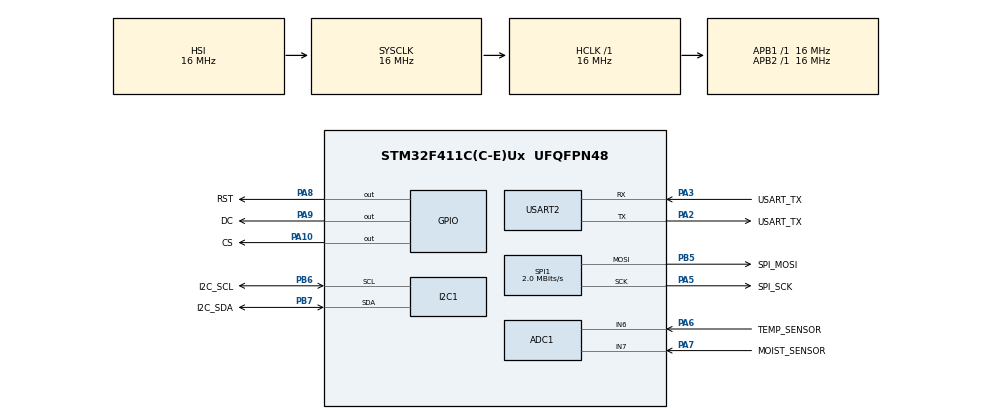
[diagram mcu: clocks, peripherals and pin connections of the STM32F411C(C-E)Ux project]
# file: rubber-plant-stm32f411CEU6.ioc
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ADC1.Channel-2\#ChannelRegularConversion=ADC_CHANNEL_6
ADC1.Channel-3\#ChannelRegularConversion=ADC_CHANNEL_7
ADC1.ClockPrescaler=ADC_CLOCK_SYNC_PCLK_DIV8
ADC1.EOCSelection=ADC_EOC_SEQ_CONV
ADC1.NbrOfConversion=2
ADC1.NbrOfConversionFlag=1
ADC1.Rank-2\#ChannelRegularConversion=1
ADC1.Rank-3\#ChannelRegularConversion=2
ADC1.SamplingTime-2\#ChannelRegularConversion=ADC_SAMPLETIME_480CYCLES
ADC1.SamplingTime-3\#ChannelRegularConversion=ADC_SAMPLETIME_480CYCLES
ADC1.ScanConvMode=ENABLE
ADC1.master=1
Dma.ADC1.0.Direction=DMA_PERIPH_TO_MEMORY
Dma.ADC1.0.FIFOMode=DMA_FIFOMODE_DISABLE
Dma.ADC1.0.Instance=DMA2_Stream0
Dma.ADC1.0.MemDataAlignment=DMA_MDATAALIGN_HALFWORD
Dma.ADC1.0.MemInc=DMA_MINC_ENABLE
Dma.ADC1.0.Mode=DMA_NORMAL
Dma.ADC1.0.PeriphDataAlignment=DMA_PDATAALIGN_HALFWORD
Dma.ADC1.0.PeriphInc=DMA_PINC_DISABLE
Dma.ADC1.0.Priority=DMA_PRIORITY_LOW
Dma.Request0=ADC1
Mcu.Family=STM32F4
Mcu.Name=STM32F411C(C-E)Ux
Mcu.Package=UFQFPN48
NVIC.DMA2_Stream0_IRQn=true\:0\:0\:false\:false\:true\:false\:true\:true
NVIC.PriorityGroup=NVIC_PRIORITYGROUP_4
PA10.GPIO_Label=CS
PA10.Signal=GPIO_Output
PA2.GPIO_Label=USART_TX
PA2.Mode=Asynchronous
PA2.Signal=USART2_TX
PA3.GPIO_Label=USART_TX
PA3.Mode=Asynchronous
PA3.Signal=USART2_RX
PA5.GPIO_Label=SPI_SCK
PA5.Mode=TX_Only_Simplex_Unidirect_Master
PA5.Signal=SPI1_SCK
PA6.GPIO_Label=TEMP_SENSOR
PA6.Signal=ADCx_IN6
PA7.GPIO_Label=MOIST_SENSOR
PA7.Signal=ADCx_IN7
PA8.GPIO_Label=RST
PA8.Signal=GPIO_Output
PA9.GPIO_Label=DC
PA9.Signal=GPIO_Output
PB5.GPIO_Label=SPI_MOSI
PB5.Mode=TX_Only_Simplex_Unidirect_Master
PB5.Signal=SPI1_MOSI
PB6.GPIO_Label=I2C_SCL
PB6.Mode=I2C
PB6.Signal=I2C1_SCL
PB7.GPIO_Label=I2C_SDA
PB7.Mode=I2C
PB7.Signal=I2C1_SDA
ProjectManager.HeapSize=0x200
ProjectManager.StackSize=0x400
ProjectManager.TargetToolchain=CMake
RCC.AHBFreq_Value=16000000
RCC.APB1Freq_Value=16000000
RCC.APB2Freq_Value=16000000
RCC.CortexFreq_Value=16000000
RCC.HSE_VALUE=25000000
RCC.HSI_VALUE=16000000
RCC.LSE_VALUE=32768
RCC.SYSCLKFreq_VALUE=16000000
RCC.VCOOutputFreq_Value=192000000
SH.ADCx_IN6.0=ADC1_IN6,IN6
SH.ADCx_IN7.0=ADC1_IN7,IN7
SPI1.BaudRatePrescaler=SPI_BAUDRATEPRESCALER_8
SPI1.CalculateBaudRate=2.0 MBits/s
SPI1.Direction=SPI_DIRECTION_2LINES
SPI1.Mode=SPI_MODE_MASTER
SPI1.VirtualType=VM_MASTER
USART2.VirtualMode=VM_ASYNC
board=custom

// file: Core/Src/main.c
/* USER CODE BEGIN Header */
/**
  ******************************************************************************
  * @file           : main.c
  * @brief          : Main program body
  ******************************************************************************
  * @attention
  *
  * Copyright (c) 2026 STMicroelectronics.
  * All rights reserved.
  *
  * This software is licensed under terms that can be found in the LICENSE file
  * in the root directory of this software component.
  * If no LICENSE file comes with this software, it is provided AS-IS.
  *
  ******************************************************************************
  */
/* USER CODE END Header */
#include "main.h"

/* USER CODE BEGIN Includes */
#include <string.h>
#include <stdio.h>
#include "stats/stats.h"
#include "stats/stats_gui.h"
#include "drivers/tsl_25911.h"
#include "drivers/waveshare_24777.h"

/* USER CODE END Includes */

ADC_HandleTypeDef hadc1;
DMA_HandleTypeDef hdma_adc1;

I2C_HandleTypeDef hi2c1;

SPI_HandleTypeDef hspi1;

UART_HandleTypeDef huart2;

void SystemClock_Config(void);
static void MX_GPIO_Init(void);
static void MX_DMA_Init(void);
static void MX_USART2_UART_Init(void);
static void MX_ADC1_Init(void);
static void MX_I2C1_Init(void);
static void MX_SPI1_Init(void);

/* USER CODE BEGIN 0 */
#define REFRESH_PERIOD_MS 100
#define OLED_CONTRAST 127

/* USER CODE END 0 */

int main(void)
{

  /* USER CODE BEGIN 1 */
  uint32_t last_refresh_ts = 0;
  SensorStats stats;
  /* USER CODE END 1 */

  /* MCU Configuration--------------------------------------------------------*/

  /* Reset of all peripherals, Initializes the Flash interface and the Systick. */
  HAL_Init();

  /* Configure the system clock */
  SystemClock_Config();

  /* Initialize all configured peripherals */
  MX_GPIO_Init();
  MX_DMA_Init();
  MX_USART2_UART_Init();
  MX_ADC1_Init();
  MX_I2C1_Init();
  MX_SPI1_Init();
  /* USER CODE BEGIN 2 */

  tsl_25911_enable_sensor_default();
  oled_enable(127);

  /* USER CODE END 2 */

  /* Infinite loop */
  while (1)
  {
    if (HAL_GetTick() - last_refresh_ts > REFRESH_PERIOD_MS) {
      get_stats(&stats);
      stats_gui_refresh(&stats);

      last_refresh_ts = HAL_GetTick();
    }
  }
}

void SystemClock_Config(void)
{
  RCC_OscInitTypeDef RCC_OscInitStruct = {0};
  RCC_ClkInitTypeDef RCC_ClkInitStruct = {0};

  /** Configure the main internal regulator output voltage
  */
  __HAL_RCC_PWR_CLK_ENABLE();
  __HAL_PWR_VOLTAGESCALING_CONFIG(PWR_REGULATOR_VOLTAGE_SCALE1);

  /** Initializes the RCC Oscillators according to the specified parameters
  * in the RCC_OscInitTypeDef structure.
  */
  RCC_OscInitStruct.OscillatorType = RCC_OSCILLATORTYPE_HSI;
  RCC_OscInitStruct.HSIState = RCC_HSI_ON;
  RCC_OscInitStruct.HSICalibrationValue = RCC_HSICALIBRATION_DEFAULT;
  RCC_OscInitStruct.PLL.PLLState = RCC_PLL_NONE;
  if (HAL_RCC_OscConfig(&RCC_OscInitStruct) != HAL_OK)
  {
    Error_Handler();
  }

  /** Initializes the CPU, AHB and APB buses clocks
  */
  RCC_ClkInitStruct.ClockType = RCC_CLOCKTYPE_HCLK|RCC_CLOCKTYPE_SYSCLK
                              |RCC_CLOCKTYPE_PCLK1|RCC_CLOCKTYPE_PCLK2;
  RCC_ClkInitStruct.SYSCLKSource = RCC_SYSCLKSOURCE_HSI;
  RCC_ClkInitStruct.AHBCLKDivider = RCC_SYSCLK_DIV1;
  RCC_ClkInitStruct.APB1CLKDivider = RCC_HCLK_DIV1;
  RCC_ClkInitStruct.APB2CLKDivider = RCC_HCLK_DIV1;

  if (HAL_RCC_ClockConfig(&RCC_ClkInitStruct, FLASH_LATENCY_0) != HAL_OK)
  {
    Error_Handler();
  }
}

static void MX_ADC1_Init(void)
{

  ADC_ChannelConfTypeDef sConfig = {0};

  /** Configure the global features of the ADC (Clock, Resolution, Data Alignment and number of conversion)
  */
  hadc1.Instance = ADC1;
  hadc1.Init.ClockPrescaler = ADC_CLOCK_SYNC_PCLK_DIV8;
  hadc1.Init.Resolution = ADC_RESOLUTION_12B;
  hadc1.Init.ScanConvMode = ENABLE;
  hadc1.Init.ContinuousConvMode = DISABLE;
  hadc1.Init.DiscontinuousConvMode = DISABLE;
  hadc1.Init.ExternalTrigConvEdge = ADC_EXTERNALTRIGCONVEDGE_NONE;
  hadc1.Init.ExternalTrigConv = ADC_SOFTWARE_START;
  hadc1.Init.DataAlign = ADC_DATAALIGN_RIGHT;
  hadc1.Init.NbrOfConversion = 2;
  hadc1.Init.DMAContinuousRequests = DISABLE;
  hadc1.Init.EOCSelection = ADC_EOC_SEQ_CONV;
  if (HAL_ADC_Init(&hadc1) != HAL_OK)
  {
    Error_Handler();
  }

  /** Configure for the selected ADC regular channel its corresponding rank in the sequencer and its sample time.
  */
  sConfig.Channel = ADC_CHANNEL_6;
  sConfig.Rank = 1;
  sConfig.SamplingTime = ADC_SAMPLETIME_480CYCLES;
  if (HAL_ADC_ConfigChannel(&hadc1, &sConfig) != HAL_OK)
  {
    Error_Handler();
  }

  /** Configure for the selected ADC regular channel its corresponding rank in the sequencer and its sample time.
  */
  sConfig.Channel = ADC_CHANNEL_7;
  sConfig.Rank = 2;
  if (HAL_ADC_ConfigChannel(&hadc1, &sConfig) != HAL_OK)
  {
    Error_Handler();
  }

}

static void MX_I2C1_Init(void)
{

  hi2c1.Instance = I2C1;
  hi2c1.Init.ClockSpeed = 100000;
  hi2c1.Init.DutyCycle = I2C_DUTYCYCLE_2;
  hi2c1.Init.OwnAddress1 = 0;
  hi2c1.Init.AddressingMode = I2C_ADDRESSINGMODE_7BIT;
  hi2c1.Init.DualAddressMode = I2C_DUALADDRESS_DISABLE;
  hi2c1.Init.OwnAddress2 = 0;
  hi2c1.Init.GeneralCallMode = I2C_GENERALCALL_DISABLE;
  hi2c1.Init.NoStretchMode = I2C_NOSTRETCH_DISABLE;
  if (HAL_I2C_Init(&hi2c1) != HAL_OK)
  {
    Error_Handler();
  }

}

static void MX_SPI1_Init(void)
{

  /* SPI1 parameter configuration*/
  hspi1.Instance = SPI1;
  hspi1.Init.Mode = SPI_MODE_MASTER;
  hspi1.Init.Direction = SPI_DIRECTION_2LINES;
  hspi1.Init.DataSize = SPI_DATASIZE_8BIT;
  hspi1.Init.CLKPolarity = SPI_POLARITY_LOW;
  hspi1.Init.CLKPhase = SPI_PHASE_1EDGE;
  hspi1.Init.NSS = SPI_NSS_SOFT;
  hspi1.Init.BaudRatePrescaler = SPI_BAUDRATEPRESCALER_8;
  hspi1.Init.FirstBit = SPI_FIRSTBIT_MSB;
  hspi1.Init.TIMode = SPI_TIMODE_DISABLE;
  hspi1.Init.CRCCalculation = SPI_CRCCALCULATION_DISABLE;
  hspi1.Init.CRCPolynomial = 10;
  if (HAL_SPI_Init(&hspi1) != HAL_OK)
  {
    Error_Handler();
  }

}

static void MX_USART2_UART_Init(void)
{

  huart2.Instance = USART2;
  huart2.Init.BaudRate = 115200;
  huart2.Init.WordLength = UART_WORDLENGTH_8B;
  huart2.Init.StopBits = UART_STOPBITS_1;
  huart2.Init.Parity = UART_PARITY_NONE;
  huart2.Init.Mode = UART_MODE_TX_RX;
  huart2.Init.HwFlowCtl = UART_HWCONTROL_NONE;
  huart2.Init.OverSampling = UART_OVERSAMPLING_16;
  if (HAL_UART_Init(&huart2) != HAL_OK)
  {
    Error_Handler();
  }

}

static void MX_DMA_Init(void)
{

  /* DMA controller clock enable */
  __HAL_RCC_DMA2_CLK_ENABLE();

  /* DMA interrupt init */
  /* DMA2_Stream0_IRQn interrupt configuration */
  HAL_NVIC_SetPriority(DMA2_Stream0_IRQn, 0, 0);
  HAL_NVIC_EnableIRQ(DMA2_Stream0_IRQn);

}

static void MX_GPIO_Init(void)
{
  GPIO_InitTypeDef GPIO_InitStruct = {0};

  /* GPIO Ports Clock Enable */
  __HAL_RCC_GPIOA_CLK_ENABLE();
  __HAL_RCC_GPIOB_CLK_ENABLE();

  /*Configure GPIO pin Output Level */
  HAL_GPIO_WritePin(GPIOA, RST_Pin|DC_Pin|CS_Pin, GPIO_PIN_RESET);

  /*Configure GPIO pins : RST_Pin DC_Pin CS_Pin */
  GPIO_InitStruct.Pin = RST_Pin|DC_Pin|CS_Pin;
  GPIO_InitStruct.Mode = GPIO_MODE_OUTPUT_PP;
  GPIO_InitStruct.Pull = GPIO_NOPULL;
  GPIO_InitStruct.Speed = GPIO_SPEED_FREQ_LOW;
  HAL_GPIO_Init(GPIOA, &GPIO_InitStruct);

}

void Error_Handler(void)
{
  __disable_irq();
  while (1)
  {
  }
}
